AUTOSAR XML (schema 00048)
package /ComponentTypes
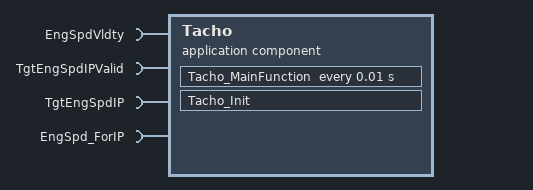
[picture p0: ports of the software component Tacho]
  application sw component type Tacho
    4 x require port:
      EngSpdVldty: nonqueued-receiver-com-spec{data-element=EngSpdVldty, alive-timeout=0.1, enable-update=true, filter=data-filter-type=ALWAYS, handle-never-received=true, init-value=0}, required-interface=EngSpdVldty
      TgtEngSpdIPValid: nonqueued-receiver-com-spec{data-element=TgtEngSpdIPValid, alive-timeout=0.1, enable-update=true, filter=data-filter-type=ALWAYS, handle-never-received=true, init-value=0}, required-interface=TgtEngSpdIPValid
      TgtEngSpdIP: nonqueued-receiver-com-spec{data-element=TgtEngSpdIP, alive-timeout=0.1, enable-update=true, filter=data-filter-type=ALWAYS, handle-never-received=true, init-value=0}, required-interface=TgtEngSpdIP
      EngSpd_ForIP: nonqueued-receiver-com-spec{data-element=EngSpd_ForIP, alive-timeout=0.1, enable-update=true, filter=data-filter-type=ALWAYS, handle-never-received=true, init-value=0}, required-interface=EngSpd_ForIP
    behavior Tacho_InternalBehavior
      init event Tacho_InitEvent: start-on-event=Tacho_Init
      timing event TMT_Tacho_MainFunction: start-on-event=Tacho_MainFunction, period=0.01
      runnable Tacho_Init
      runnable Tacho_MainFunction
        data-receive-point-by-arguments:
          4 x access:
            REC_EngSpdVldty_EngSpdVldty: accessed-variable=EngSpdVldty.EngSpdVldty
            REC_TgtEngSpdIPValid_TgtEngSpdIPValid: accessed-variable=TgtEngSpdIPValid.TgtEngSpdIPValid
            REC_EngSpd_ForIP_EngSpd_ForIP: accessed-variable=EngSpd_ForIP.EngSpd_ForIP
            REC_TgtEngSpdIP_TgtEngSpdIP: accessed-variable=TgtEngSpdIP.TgtEngSpdIP
  swc implementation Tacho_Implementation: behavior=Tacho_InternalBehavior
